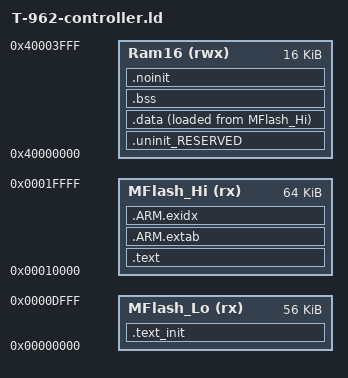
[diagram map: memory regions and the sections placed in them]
/**
 * Linker script for the T-962 controller improved firmware.
 *
 * Amended from a version generated by LPCXpresso v7.5.0
 *
 * LPC2134 Flash layout (128KB, 11 sectors):
 *   Sectors 0-6: 8KB each = 56KB  -> MFlash_Lo  (firmware low)
 *   Sector  7:   8KB              -> reserved for IAP profile storage
 *   Sectors 8-10: remaining 64KB  -> MFlash_Hi  (firmware high)
 */

GROUP(
	libgcc.a
	libc_nano.a
	libm.a
	libnosys.a
)

MEMORY {
  /* Firmware code: sectors 0-6 (56KB) + sectors 8-10 (64KB) = 120KB total */
  MFlash_Lo (rx)     : ORIGIN = 0x0,     LENGTH = 0xE000  /* 56KB, sectors 0-6 */
  /* Sector 7 (0xE000-0xFFFF) reserved for flash profile storage - do NOT place code here */
  MFlash_Hi (rx)     : ORIGIN = 0x10000, LENGTH = 0x10000 /* 64KB, sectors 8-10 */
  Ram16 (rwx)        : ORIGIN = 0x40000000, LENGTH = 0x4000 /* 16K bytes */
}
  /* Define a symbol for the top of each memory region */
  __top_MFlash_Lo = 0x0 + 0xE000;
  __top_MFlash_Hi = 0x10000 + 0x10000;
  __top_Ram16 = 0x40000000 + 0x4000;

ENTRY(_start)

SECTIONS
{

    /* VECTORS + BOOTSTRAP - placed in low flash (sectors 0-6) */
    .text_init : ALIGN(4)
    {
        FILL(0xff)
        __vectors_start__ = ABSOLUTE(.) ;
        KEEP(*(.isr_vector))

        /* Global Section Table */
        . = ALIGN(4) ;
        __section_table_start = .;
        __data_section_table = .;
        LONG(LOADADDR(.data));
        LONG(    ADDR(.data));
        LONG(  SIZEOF(.data));
        __data_section_table_end = .;
        __bss_section_table = .;
        LONG(    ADDR(.bss));
        LONG(  SIZEOF(.bss));
        __bss_section_table_end = .;
        __section_table_end = . ;
        /* End of Global Section Table */


        *(.after_vectors*)

        /* Code Read Protect data */
        . = 0x000001FC ;
        PROVIDE(__CRP_WORD_START__ = .) ;
        KEEP(*(.crp))
        PROVIDE(__CRP_WORD_END__ = .) ;
        /*
        Disabled: We're using newlib, not redlib.
        ASSERT(!(__CRP_WORD_START__ == __CRP_WORD_END__), "Linker CRP Enabled, but no CRP_WORD provided within application"); */
        /* End of Code Read Protect */

    } >MFlash_Lo

    /* MAIN CODE SECTION - placed in high flash (sectors 8-10) */
    .text : ALIGN(4)
    {
         *(.text*)
        *(.rodata .rodata.* .constdata .constdata.*)
        . = ALIGN(4);

    } > MFlash_Hi

    /*
     * for exception handling/unwind - some Newlib functions (in common
     * with C++ and STDC++) use this.
     */
    .ARM.extab : ALIGN(4)
    {
        *(.ARM.extab* .gnu.linkonce.armextab.*)
    } > MFlash_Hi
    __exidx_start = .;

    .ARM.exidx : ALIGN(4)
    {
        *(.ARM.exidx* .gnu.linkonce.armexidx.*)
    } > MFlash_Hi
    __exidx_end = .;

    _etext = .;


    /* MAIN DATA SECTION */


    .uninit_RESERVED : ALIGN(4)
    {
        KEEP(*(.bss.$RESERVED*))
        . = ALIGN(4) ;
        _end_uninit_RESERVED = .;
    } > Ram16


    /* Main DATA section (Ram16) */
    .data : ALIGN(4)
    {
       FILL(0xff)
       _data = . ;
       *(vtable)
       *(.ramfunc*)
       *(.data*)
       . = ALIGN(4) ;
       _edata = . ;
    } > Ram16 AT>MFlash_Hi


    /* MAIN BSS SECTION */
    .bss : ALIGN(4)
    {
        _bss = .;
        *(.bss*)
        *(COMMON)
        . = ALIGN(4) ;
        _ebss = .;
        PROVIDE(end = .);
    } > Ram16


    /* DEFAULT NOINIT SECTION */
    .noinit (NOLOAD): ALIGN(4)
    {
        _noinit = .;
        *(.noinit*)
         . = ALIGN(4) ;
        _end_noinit = .;
    } > Ram16

    PROVIDE(_pvHeapStart = DEFINED(__user_heap_base) ? __user_heap_base : .);
    PROVIDE(_vStackTop = DEFINED(__user_stack_top) ? __user_stack_top : __top_Ram16 - 0);
}
